# SN32F290 register map
Vendor: SONIX; File version: 2026.10.03
CPU: CM0 r0p0, little endian, 2 interrupt priority bits
Registers are 32-bit, read-write, reset 0x0 unless marked. A register's access mark holds for its fields unless they carry their own. Offsets are from the block's base; [hi:lo] are bit positions; lines under a group give offsets from that group.

## SN_CMP — Comparator
Base 0x40028000
0x00 CTRL reset 0x20002 (reset mask 0x1FFF1FFF) — Offset:0x00 CMP Control Register
  [56:28] CM1G — CMP1 interrupt trigger direction control bit
    0=Falling range trigger (CMP1 output status is from high to low as VPREF1 less than CM1N); 1=Rising edge trigger (CMP1 output status is from low to high as VPREF1 more than CM1N)
  [53:26] CM1OEN — CMP1 Output pin control bits
    0=Disable CM1O; 1=P2.2 (P2.2 is CM1O and isolate GPIO function); 2=P2.7 (P2.7 is CM1O and isolate GPIO function); 3=P3.4 (P3.4 is CM1O and isolate GPIO function)
  [46:21] CM1RS — CMP1 internal reference voltage (VIREF1) selection bits
    0=00000b (VIREF1=VIREF); 1=00001b (VIREF1=VIREF*1/32); 10=01010b (VIREF1=VIREF*10/32); 11=01011b (VIREF1=VIREF*11/32); 12=01100b (VIREF1=VIREF*12/32); 13=01101b (VIREF1=VIREF*13/32); 14=01110b (VIREF1=VIREF*14/32); 15=01111b (VIREF1=VIREF*15/32); 16=10000b (VIREF1=VIREF*16/32); 17=10001b (VIREF1=VIREF*17/32); 18=10010b (VIREF1=VIREF*18/32); 19=10011b (VIREF1=VIREF*19/32); 2=00010b (VIREF1=VIREF*2/32); 20=10100b (VIREF1=VIREF*20/32); 21=10101b (VIREF1=VIREF*21/32); 22=10110b (VIREF1=VIREF*22/32); 23=10111b (VIREF1=VIREF*23/32); 24=11000b (VIREF1=VIREF*24/32); 25=11001b (VIREF0=VIREF*25/32); 26=11010b (VIREF1=VIREF*26/32); 27=11011b (VIREF1=VIREF*27/32); 28=11100b (VIREF1=VIREF*28/32); 29=11101b (VIREF1=VIREF*29/32); 3=00011b (VIREF1=VIREF*3/32); 30=11110b (VIREF1=VIREF*30/32); 31=11111b (VIREF1=VIREF*31/32); 4=00100b (VIREF1=VIREF*4/32); 5=00101b (VIREF1=VIREF*5/32); 6=00110b (VIREF1=VIREF*6/32); 7=00111b (VIREF1=VIREF*7/32); 8=01000b (VIREF1=VIREF*8/32); 9=01001b (VIREF1=VIREF*9/32)
  [39:19] CM1NS — CMP1 Negative input pin
    0=CM1N0; 1=CM1N1; 2=CM1N2; 3=VIREF1 (CM1N0/CM1N1/CM1N2 pins are GPIO mode)
  [35:17] CM1PS — CMP1 Positive input selection bits
    0=No (CM1P0/CM1P1/CM1P2 pins are GPIO mode); 1=CM1P0 (CM1P0 is positive input pin); 2=CM1P1 (CM1P1 is positive input pin); 3=CM1P2 (CM1P2 is positive input pin)
  [32:16] CM1EN — CMP1 Enable bit
    0=Disable CMP1; 1=Enable CMP1
  [24:12] CM0G — CMP0 interrupt trigger direction control bit
    0=Falling range trigger (CMP0 output status is from high to low as VPREF0 less than CM0N); 1=Rising edge trigger (CMP0 output status is from low to high as VPREF0 more than CM0N)
  [21:10] CM0OEN — CMP0 Output pin control bits
    0=Disable CM0O; 1=P2.0 (P2.0 is CM0O and isolate GPIO function); 2=P2.6 (P2.6 is CM0O and isolate GPIO function); 3=P3.3 (P3.3 is CM0O and isolate GPIO function)
  [14:5] CM0RS — CMP0 internal reference voltage (VIREF0) selection bits
    0=00000b (VIREF0=VIREF); 1=00001b (VIREF0=VIREF*1/32); 10=01010b (VIREF0=VIREF*10/32); 11=01011b (VIREF0=VIREF*11/32); 12=01100b (VIREF0=VIREF*12/32); 13=01101b (VIREF0=VIREF*13/32); 14=01110b (VIREF0=VIREF*14/32); 15=01111b (VIREF0=VIREF*15/32); 16=10000b (VIREF0=VIREF*16/32); 17=10001b (VIREF0=VIREF*17/32); 18=10010b (VIREF0=VIREF*18/32); 19=10011b (VIREF0=VIREF*19/32); 2=00010b (VIREF0=VIREF*2/32); 20=10100b (VIREF0=VIREF*20/32); 21=10101b (VIREF0=VIREF*21/32); 22=10110b (VIREF0=VIREF*22/32); 23=10111b (VIREF0=VIREF*23/32); 24=11000b (VIREF0=VIREF*24/32); 25=11001b (VIREF0=VIREF*25/32); 26=11010b (VIREF0=VIREF*26/32); 27=11011b (VIREF0=VIREF*27/32); 28=11100b (VIREF0=VIREF*28/32); 29=11101b (VIREF0=VIREF*29/32); 3=00011b (VIREF0=VIREF*3/32); 30=11110b (VIREF0=VIREF*30/32); 31=11111b (VIREF0=VIREF*31/32); 4=00100b (VIREF0=VIREF*4/32); 5=00101b (VIREF0=VIREF*5/32); 6=00110b (VIREF0=VIREF*6/32); 7=00111b (VIREF0=VIREF*7/32); 8=01000b (VIREF0=VIREF*8/32); 9=01001b (VIREF0=VIREF*9/32)
  [7:3] CM0NS — CMP0 Negative input pin
    0=CM0N0 (CM0N0 is negative input pin); 1=CM0N1 (CM0N1 is negative input pin); 2=CM0N2 (CM0N2 is negative input pin); 3=VIREF0 (CM0N0/CM0N1/CM0N2 pins are GPIO mode)
  [3:1] CM0PS — CMP0 Positive input selection bits
    0=No (CM0P0/CM0P1/CM0P2 pins are GPIO mode); 1=CM0P0 (CM0P0 is positive input pin); 2=CM0P1 (CM0P1 is positive input pin); 3=CM0P2 (CM0P2 is positive input pin)
  [0] CM0EN — CMP0 Enable bit
    0=Disable CMP0; 1=Enable CMP0
0x04 CTRL1 reset 0x2 (reset mask 0x1FFF) — Offset:0x04 CMP Control Register 1
  [24:12] CM2G — CMP2 interrupt trigger direction control bit
    0=Falling range trigger (CMP2 output status is from high to low as VPREF2 less than CM2N); 1=Rising edge trigger (CMP2 output status is from low to high as VPREF2 more than CM2N)
  [21:10] CM2OEN — CMP2 Output pin control bits
    0=Disable CM2O; 1=P0.12 (P0.12 is CM2O and isolate GPIO function); 2=P0.3 (P0.3 is CM2O and isolate GPIO function); 3=P3.8 (P3.8 is CM2O and isolate GPIO function)
  [14:5] CM2RS — CMP2 internal reference voltage (VIREF2) selection bits
    0=00000b (VIREF2=VIREF); 1=00001b (VIREF2=VIREF*1/32); 10=01010b (VIREF2=VIREF*10/32); 11=01011b (VIREF2=VIREF*11/32); 12=01100b (VIREF2=VIREF*12/32); 13=01101b (VIREF2=VIREF*13/32); 14=01110b (VIREF2=VIREF*14/32); 15=01111b (VIREF2=VIREF*15/32); 16=10000b (VIREF2=VIREF*16/32); 17=10001b (VIREF2=VIREF*17/32); 18=10010b (VIREF2=VIREF*18/32); 19=10011b (VIREF2=VIREF*19/32); 2=00010b (VIREF2=VIREF*2/32); 20=10100b (VIREF2=VIREF*20/32); 21=10101b (VIREF2=VIREF*21/32); 22=10110b (VIREF2=VIREF*22/32); 23=10111b (VIREF2=VIREF*23/32); 24=11000b (VIREF2=VIREF*24/32); 25=11001b (VIREF2=VIREF*25/32); 26=11010b (VIREF2=VIREF*26/32); 27=11011b (VIREF2=VIREF*27/32); 28=11100b (VIREF2=VIREF*28/32); 29=11101b (VIREF2=VIREF*29/32); 3=00011b (VIREF2=VIREF*3/32); 30=11110b (VIREF2=VIREF*30/32); 31=11111b (VIREF2=VIREF*31/32); 4=00100b (VIREF2=VIREF*4/32); 5=00101b (VIREF2=VIREF*5/32); 6=00110b (VIREF2=VIREF*6/32); 7=00111b (VIREF2=VIREF*7/32); 8=01000b (VIREF2=VIREF*8/32); 9=01001b (VIREF2=VIREF*9/32)
  [7:3] CM2NS — CMP2 Negative input pin
    0=CM2N0; 1=CM2N1; 2=CM2N2; 3=VIREF2 (CM2N0/CM2N1/CM2N2 pins are GPIO mode)
  [3:1] CM2PS — CMP2 Positive input selection bits
    0=No (CM2P0/CM2P1/CM2P2 pins are GPIO mode); 1=CM2P0 (CM2P0 is positive input pin); 2=CM2P1 (CM2P1 is positive input pin); 3=CM2P2 (CM2P2 is positive input pin)
  [0] CM2EN — CMP2 Enable bit
    0=Disable CMP2; 1=Enable CMP2
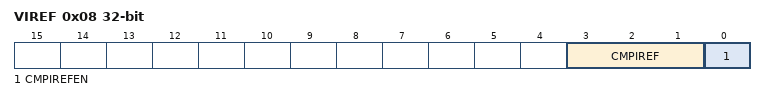
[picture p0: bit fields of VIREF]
0x08 VIREF (reset mask 0x7) — Offset:0x08 CMP Internal Reference Voltage register
  [3:1] CMPIREF — CMP internal reference voltage (VIREF) source
    0=VDD (VIREF=VDD); 1=Internal 1P5V (VIREF=Internal 1P5V); 2=Internal 2V (VIREF=Internal 2V); 3=Internal 3V (VIREF=Internal 3V)
  [0] CMPIREFEN — CMP internal reference voltage (VIREF) enable
    0=Disable CMP internal reference voltage; 1=Enable CMP internal reference voltage
0x0C OS ro (reset mask 0x7) — Offset:0xC CMP Output Status Register
  [4:2] CM2OUT — CMP2 Output flag bit
    0=CMP2 V+ is less than V- (V2+ is less than V2- voltage); 1=CMP2 V+ is more than V- (V2+ is more than V2- voltage)
  [2:1] CM1OUT — CMP1 Output flag bit
    0=CMP1 V+ is less than V- (V1+ is less than V1-); 1=CMP1 V+ is more than V- (V1+ is more than V1- voltage)
  [0] CM0OUT — CMP0 Output flag bit
    0=CMP0 V+ is less than V- (V0+ is less than V0-); 1=CMP0 V+ is more than V- (V0+ is more than V0-)
0x10 IE (reset mask 0xF) — Offset:0x10 CMP Interrupt Enable Register
  [6:3] CSIE — Cap-sensing interrupt enable
    0=Disable CS interrupt; 1=Enable CS interrupt
  [4:2] CM2IE — CMP2 interrupt enable
    0=Disable CMP2 interrupt; 1=Enable CMP2 interrupt
  [2:1] CM1IE — CMP1 interrupt enable
    0=Disable CMP1 interrupt; 1=Enable CMP1 interrupt
  [0] CM0IE — CMP0 interrupt enable
    0=Disable CMP0 interrupt; 1=Enable CMP0 interrupt
0x14 RIS ro (reset mask 0xF) — Offset:0x14 CMP n Raw Interrupt Status Register
  [6:3] CSIF — Cap-sensing raw interrupt flag
    0=No interrupt on Cap-sensing function; 1=Met interrupt requirements (Interrupt requirements met on Cap-sensing function)
  [4:2] CM2IF — CMP2 raw interrupt flag
    0=No interrupt on CMP2; 1=Met interrupt requirements (Interrupt requirements met on CMP2)
  [2:1] CM1IF — CMP1 raw interrupt flag
    0=No interrupt on CMP1; 1=Met interrupt requirements (Interrupt requirements met on CMP1)
  [0] CM0IF — CMP0 raw interrupt flag
    0=No interrupt on CMP0; 1=Met interrupt requirements (Interrupt requirements met on CMP0)
0x18 IC wo (reset mask 0xF) — Offset:0x18 CMP Interrupt Clear Register
  [6:3] CSIC — Cap-sensing interrupt flag clear bit
    0=No effect; 1=Clear CS interrupt flag
  [4:2] CM2IC — CMP2 interrupt flag clear bit
    0=No effect; 1=Clear CMP2 interrupt flag
  [2:1] CM1IC — CMP1 interrupt flag clear bit
    0=No effect; 1=Clear CMP1 interrupt flag
  [0] CM0IC — CMP0 interrupt flag clear bit
    0=No effect; 1=Clear CMP0 interrupt flag
0x1C DB (reset mask 0x1F777) — Offset:0x1C CMP Interrupt Clear Register
  [28:12] CSDB — Count for Cap-sensing output debounce time
    0=00000b (No Cap-sening output debounce time); 1=00001b (Cap-sensing output debounce time=1*CS_PCLK); 10=01010b (Cap-sensing output debounce time=10*CS_PCLK); 11=01011b (Cap-sensing output debounce time=11*CS_PCLK); 12=01100b (Cap-sensing output debounce time=12*CS_PCLK); 13=01101b (Cap-sensing output debounce time=13*CS_PCLK); 14=01110b (Cap-sensing output debounce time=14*CS_PCLK); 15=01111b (Cap-sensing output debounce time=15*CS_PCLK); 16=10000b (Cap-sensing output debounce time=16*CS_PCLK); 17=10001b (Cap-sensing output debounce time=17*CS_PCLK); 18=10010b (Cap-sensing output debounce time=18*CS_PCLK); 19=10011b (Cap-sensing output debounce time=19*CS_PCLK); 2=00010b (Cap-sensing output debounce time=2*CS_PCLK); 20=10100b (Cap-sensing output debounce time=20*CS_PCLK); 21=10101b (Cap-sensing output debounce time=21*CS_PCLK); 22=10110b (Cap-sensing output debounce time=22*CS_PCLK); 23=10111b (Cap-sensing output debounce time=23*CS_PCLK); 24=11000b (Cap-sensing output debounce time=24*CS_PCLK); 25=11001b (Cap-sensing output debounce time=25*CS_PCLK); 26=11010b (Cap-sensing output debounce time=26*CS_PCLK); 27=11011b (Cap-sensing output debounce time=27*CS_PCLK); 28=11100b (Cap-sensing output debounce time=28*CS_PCLK); 29=11101b (Cap-sensing output debounce time=29*CS_PCLK); 3=00011b (Cap-sensing output debounce time=3*CS_PCLK); 30=11110b (Cap-sensing output debounce time=30*CS_PCLK); 31=11111b (Cap-sensing output debounce time=31*CS_PCLK); 4=00100b (Cap-sensing output debounce time=4*CS_PCLK); 5=00101b (Cap-sensing output debounce time=5*CS_PCLK); 6=00110b (Cap-sensing output debounce time=6*CS_PCLK); 7=00111b (Cap-sensing output debounce time=7*CS_PCLK); 8=01000b (Cap-sensing output debounce time=8*CS_PCLK); 9=01001b (Cap-sensing output debounce time=9*CS_PCLK)
  [18:8] CM2DB — Count for CMP2 output debounce time
    0=000b (No CMP2 output debounce time); 1=001b (CMP2 output debounce time=2*CMP2_PCLK); 2=010b (CMP2 output debounce time=4*CMP2_PCLK); 3=011b (CMP2 output debounce time=8*CMP2_PCLK); 4=100b (CMP2 output debounce time=16*CMP2_PCLK); 5=101b (CMP2 output debounce time=32*CMP2_PCLK); 6=110b (CMP2 output debounce time=64*CMP2_PCLK); 7=111b (CMP2 output debounce time=128*CMP2_PCLK)
  [10:4] CM1DB — Count for CMP1 output debounce time
    0=000b (No CMP1 output debounce time); 1=001b (CMP1 output debounce time=2*CMP1_PCLK); 2=010b (CMP1 output debounce time=4*CMP1_PCLK); 3=011b (CMP1 output debounce time=8*CMP1_PCLK); 4=100b (CMP1 output debounce time=16*CMP1_PCLK); 5=101b (CMP1 output debounce time=32*CMP1_PCLK); 6=110b (CMP1 output debounce time=64*CMP1_PCLK); 7=111b (CMP1 output debounce time=128*CMP1_PCLK)
  [2:0] CM0DB — Count for CMP0 output debounce time
    0=000b (No CMP0 output debounce time); 1=001b (CMP0 output debounce time=2*CMP0_PCLK); 2=010b (CMP0 output debounce time=4*CMP0_PCLK); 3=011b (CMP0 output debounce time=8*CMP0_PCLK); 4=100b (CMP0 output debounce time=16*CMP0_PCLK); 5=101b (CMP0 output debounce time=32*CMP0_PCLK); 6=110b (CMP0 output debounce time=64*CMP0_PCLK); 7=111b (CMP0 output debounce time=128*CMP0_PCLK)
0x20 CSCTRL reset 0x47600 (reset mask 0xC7FFF8FF) — Offset:0x20 CMP Cap-sensing Control Register
  [62:31] CSRDY ro — Cap-sensing module ready flag
    0=Not Ready (Cap-sensing module are not ready); 1=Ready (Cap-sensing module are ready)
  [60:30] CSFAPC — CSF active controll
    0=Disable (CSF can be triggered any time); 1=Enable (CSF can be triggered while CSS is high.)
  [52:26] CSDIS — Channel discharge signl (CK_TCH) controll bit
    0=Enable; 1=Disable
  [50:25] CSOUTEN — Cap-sening output pin enable bit
    0=Disable (CSOUT pin is GPIO); 1=Enable (CSOUT pin is Cap-sensing output pin)
  [48:24] CCAL4 — Cap Calibration select bit
    0=VSS (Cap Calibration circuit is connect to VSS); 1=VDD (Cap Calibration circuit is connect to VDD)
  [43:20] CCAL — Cap Calibration parameter
    0=0000b (0pF); 1=0001b (0.2pF); 10=1010b (2.0pF); 11=1011b (2.2pF); 12=1100b (2.4pF); 13=1101b (2.6pF); 14=1110b (2.8pF); 15=1111b (3.0pF); 2=0010b (0.4pF); 3=0011b (0.6pF); 4=0100b (0.8pF); 5=0101b (1.0pF); 6=0110b (1.2pF); 7=0111b (1.4pF); 8=1000b (1.6pF); 9=1001b (1.8pF)
  [37:18] TNON — Non-overlap time
    0=13ns; 1=26ns; 2=39ns; 3=52ns
  [32:15] CHG — Cap-sensing charging time
    0=000b (2us); 1=001b (4us); 2=010b (8us); 3=011b (16us); 4=100b (32us); 5=101b (64us); 6=110b (128us); 7=111b (256us)
  [28:14] VDSEL — Cap-sensing voltage detects select bit
    1=Comparator (Cap-sensing voltage is detected by Comparator)
  [24:11] CMP — Comparator reference control bits
    0=000b (0.3083*VREG33); 1=001b (0.3583*VREG33); 2=010b (0.3917*VREG33); 3=011b (0.4417*VREG33); 4=100b (0.5083*VREG33); 5=101b (0.5583*VREG33); 6=110b (0.5917*VREG33); 7=111b (0.6417*VREG33)
  [10:3] CSH — Cap-sensing channel
    0=00000b (CT0); 1=00001b (CT1); 10=01010b (CT10); 11=01011b (CT11); 12=01100b (CT12); 13=01101b (CT13); 14=01110b (CT14); 15=01111b (CT15); 16=10000b (CT16); 17=10001b (CT17); 18=10010b (CT18); 19=10011b (CT19); 2=00010b (CT2); 20=10100b (CT20); 21=10101b (CT21); 22=10110b (CT22); 23=10111b (CT23); 24=11000b (CT24 (Internal reference channel)); 3=00011b (CT3); 4=00100b (CT4); 5=00101b (CT5); 6=00110b (CT6); 7=00111b (CT7); 8=01000b (CT8); 9=01001b (CT9)
  [4:2] CS1ST — Cap-sensing channel scan group start bit
    0=Not New (Not group scan start); 1=New (New group scan start)
  [2:1] CSS — Cap-sensing operation start bit
    0=Stop (Cap-sensing operation stops); 1=Start (Cap-sensing operation starts)
  [0] CSEN — Cap-sensing module enable bit
    0=Disable CS module; 1=Enable CS module
0x24 CSCTRL1 (reset mask 0x7FC3) — Offset:0x24 CMP Cap-sensing Control Register 1
  [28:14] CSCOV — CSC 16-bit timer counter overflow indicator (Clock source is CS_PCLK)
    0=No (No overflow); 1=Overflow (CSC[15:0] timer counter overflows)
  [26:13] CSVCOV — CSV 16-bit event counter overflow indicator (Clock source is Cap-sensing 4MHz)
    0=No (No overflow); 1=Overflow (CSV[15:0] event counter overflows)
  [20:8] OSCR — Ring OSC.4MHz clock range
    0=00000b (4.096MHz); 1=00001b (3.973MHz); 10=01010b (4.427MHz); 11=01011b (4.299MHz); 12=01100b (3.808MHz); 13=01101b (3.714MHz); 14=01110b (3.715MHz); 15=01111b (3.626MHz); 16=10000b (5.157MHz); 17=10001b (5.004MHz); 18=10010b (5.004MHz); 19=10011b (4.860MHz); 2=00010b (3.973MHz); 20=10100b (4.308MHz); 21=10101b (4.203MHz); 22=10110b (4.203MHz); 23=10111b (4.103MHz); 24=11000b (6.416MHz); 25=11001b (6.227MHz); 26=11010b (6.227MHz); 27=11011b (6.051MHz); 28=11100b (5.372MHz); 29=11101b (5.243MHz); 3=00011b (3.857MHz); 30=11110b (5.243MHz); 31=11111b (5.120MHz); 4=00100b (3.414MHz); 5=00101b (3.329MHz); 6=00110b (3.330MHz); 7=00111b (3.250MHz); 8=01000b (4.564MHz); 9=01001b (4.428MHz)
  [13:6] SGSEL — Cap-sensing 4MHz clock source and SSCG select bit
    0=00b (4MHz IHRC and disable PRBS function); 2=10b (4MHz Ring OSC. and disable PRBS function)
  [1:0] SGFRQ — Spread Spectrum frequency
    0=00b (4MHz); 1=01b (2MHz); 2=10b (1MHz); 3=11b (0.5MHz)
0x28 CSCNT ro — Offset:0x28 CMP CapSensing Counter Register
  [47:16] CSC — CSC 16-bit timer counter (CSC counter clock source is CS_PCLK)
  [15:0] CSV — CSV 16-bit event counter (CSV counter clock source is CS_4MHz)
